# K1921VG1T register map
Vendor: NIIET; Series: K1921VGx; File version: 2.8
CPU: other r0p1, little endian, MPU, FPU, 4 interrupt priority bits
Registers are 32-bit, read-write, reset 0x0 unless marked. A register's access mark holds for its fields unless they carry their own. Offsets are from the block's base; [hi:lo] are bit positions; lines under a group give offsets from that group; {n}, {i} and the like mark numbered series; <NAME> marks a mode.

## CANMSG — CAN message registers
Base 0x41011000
{0x0+0x20*i} Msg[{i}] (i=0..255) group
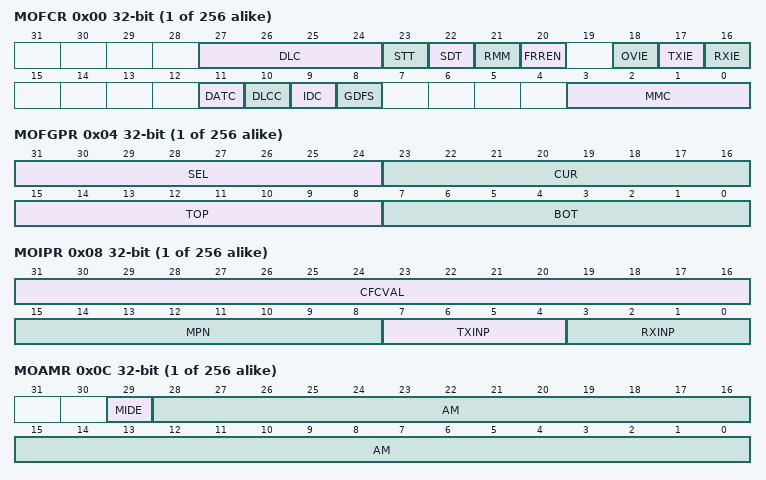
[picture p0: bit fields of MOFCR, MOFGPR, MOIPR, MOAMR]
  0x00 MOFCR — Register control the operation of the message object 0
    [27:24] DLC — Data length code
    [23] STT — Bit single data transfer
    [22] SDT — Bit single of the message object <i> participation in shipment
    [21] RMM — Enable remote monitoring of the communication object
    [20] FRREN — Enable remote request
    [18] OVIE — Interrupt enable FIFO to fill the message object <i>
    [17] TXIE — Interrupt enable at the end of the message
    [16] RXIE — Interrupt enable after taking the messages
    [11] DATC
    [10] DLCC
    [9] IDC
    [8] GDFS
    [3:0] MMC
      0=MsgObj (message object); 1=RXObj (receiver FIFO structure object); 2=TXObj (transmitter FIFO structure object); 3=SlaveTXObj (transmitter FIFO structure slave object); 4=SrcObj (gateway source object)
  0x04 MOFGPR — Pointer register FIFO / gateway message object 0
    [31:24] SEL — Object pointer message
    [23:16] CUR — A pointer to the current object within the FIFO or gateway
    [15:8] TOP — FIFO pointer to the top element
    [7:0] BOT — FIFO pointer to the lower element
  0x08 MOIPR — Pointer register interrupt message object 0
    [31:16] CFCVAL — Number of frames
    [15:8] MPN — Number message waiting bit
    [7:4] TXINP — Pointer interrupt line to interrupt after transfer
    [3:0] RXINP — Pointer interrupt line to interrupt after receiving
  0x0C MOAMR — Mask register message object 0
    [29] MIDE — Mask bit IDE message
    [28:0] AM — Mask ID
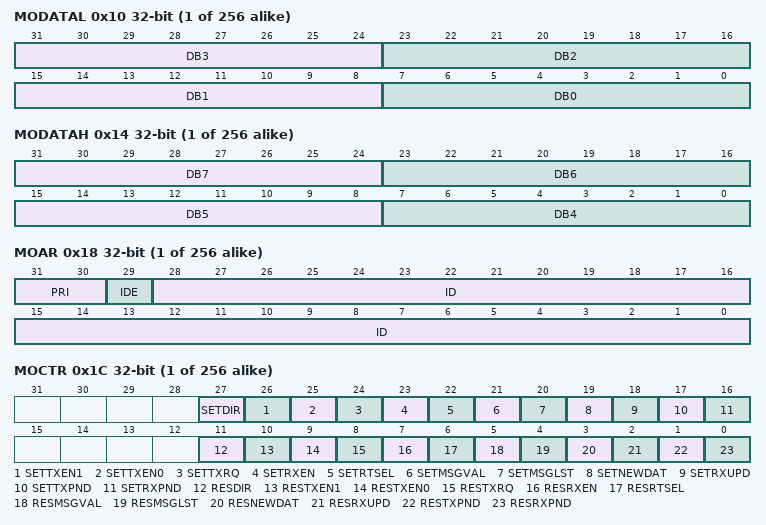
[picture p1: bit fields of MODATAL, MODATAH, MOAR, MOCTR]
  0x10 MODATAL — Low data registers of the message object 0
    [31:24] DB3 — The third data byte
    [23:16] DB2 — Second data byte
    [15:8] DB1 — The first data byte
    [7:0] DB0 — Zero byte data
  0x14 MODATAH — High data registers of the message object 0
    [31:24] DB7 — Seventh byte of data
    [23:16] DB6 — Sixth byte data
    [15:8] DB5 — Fifth byte data
    [7:0] DB4 — The fourth data byte
  0x18 MOAR — Register arbitration message object 0
    [31:30] PRI — Priority class
    [29] IDE — Bit extension identifier of the message object <i>
    [28:0] ID — Object ID message <i>
  0x1C MOCTR wo — Control register Message object 0
    [27] SETDIR — Set bit DIR
    [26] SETTXEN1 — Set bit TXEN1
    [25] SETTXEN0 — Set bit TXEN0
    [24] SETTXRQ — Set bit TXRQ
    [23] SETRXEN — Set bit RXEN
    [22] SETRTSEL — Set bit RTSEL
    [21] SETMSGVAL — Set bit MSGVAL
    [20] SETMSGLST — Set bit MSGLST
    [19] SETNEWDAT — Set bit NEWDAT
    [18] SETRXUPD — Set bit RXUPD
    [17] SETTXPND — Set bit TXPND
    [16] SETRXPND — Set bit RXPND
    [11] RESDIR — Reset bit DIR
    [10] RESTXEN1 — Reset bit TXEN1
    [9] RESTXEN0 — Reset bit TXEN0
    [8] RESTXRQ — Reset bit TXRQ
    [7] RESRXEN — Reset bit RXEN
    [6] RESRTSEL — Reset bit RTSEL
    [5] RESMSGVAL — Reset bit MSGVAL
    [4] RESMSGLST — Reset bit MSGLST
    [3] RESNEWDAT — Reset bit NEWDAT
    [2] RESRXUPD — Reset bit RXUPD
    [1] RESTXPND — Reset bit TXPND
    [0] RESRXPND — Reset bit RXPND
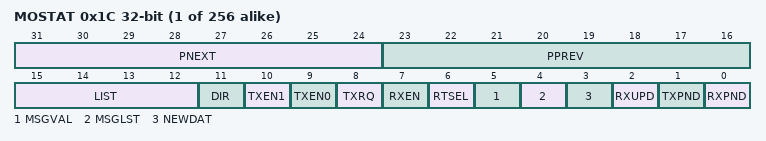
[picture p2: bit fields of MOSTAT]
  0x1C MOSTAT ro (alternate view of MOCTR) — Status register of the message object 0
    [31:24] PNEXT — Pointer to the next item in the list
    [23:16] PPREV — Pointer to the previous entry
    [15:12] LIST — Number list the message object <i>
    [11] DIR — Bit allocation
    [10] TXEN1 — Enable bit transmission frame
    [9] TXEN0 — Enable bit transmission frame
    [8] TXRQ — Initiate transmission
    [7] RXEN — Bits allow reception
    [6] RTSEL — The indication of transmission / reception
    [5] MSGVAL — Activity bit of the message object <i>
    [4] MSGLST — Bit message loss
    [3] NEWDAT — New data indicator
    [2] RXUPD — Indicator changes
    [1] TXPND — Indicator end of transmission
    [0] RXPND — Indicator deadline
